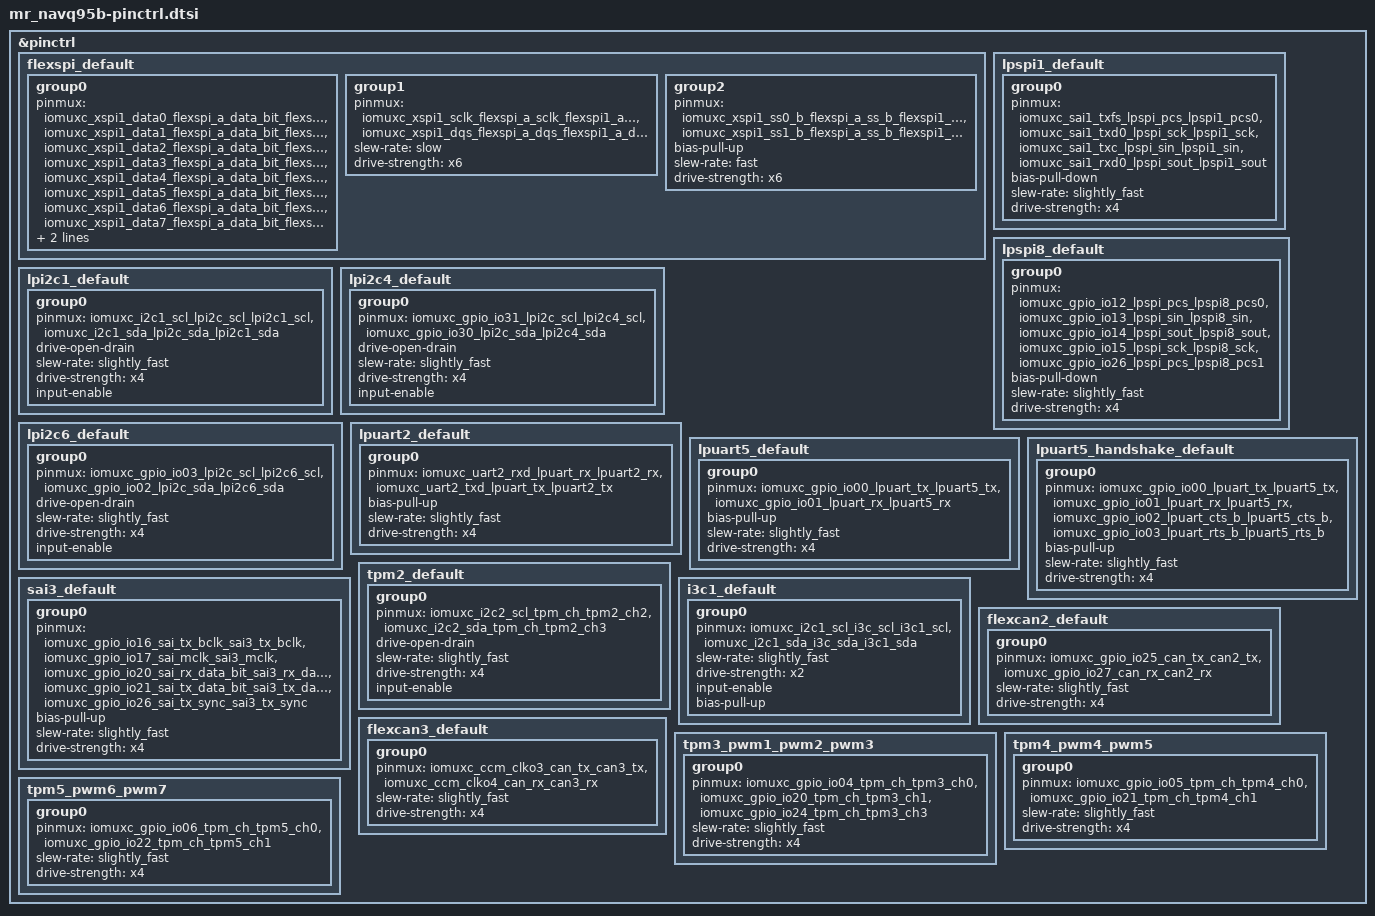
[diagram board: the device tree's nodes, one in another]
/*
 * Copyright 2026 NXP
 *
 * SPDX-License-Identifier: Apache-2.0
 */

#include <nxp/nxp_imx/mimx9596avzxn-pinctrl.dtsi>

&pinctrl {
	flexspi_default: flexspi_default {
		group0 {
			pinmux = <&iomuxc_xspi1_data0_flexspi_a_data_bit_flexspi1_a_data_bit0>,
				 <&iomuxc_xspi1_data1_flexspi_a_data_bit_flexspi1_a_data_bit1>,
				 <&iomuxc_xspi1_data2_flexspi_a_data_bit_flexspi1_a_data_bit2>,
				 <&iomuxc_xspi1_data3_flexspi_a_data_bit_flexspi1_a_data_bit3>,
				 <&iomuxc_xspi1_data4_flexspi_a_data_bit_flexspi1_a_data_bit4>,
				 <&iomuxc_xspi1_data5_flexspi_a_data_bit_flexspi1_a_data_bit5>,
				 <&iomuxc_xspi1_data6_flexspi_a_data_bit_flexspi1_a_data_bit6>,
				 <&iomuxc_xspi1_data7_flexspi_a_data_bit_flexspi1_a_data_bit7>;
			slew-rate = "slow";
			drive-strength = "x1";
		};

		group1 {
			pinmux = <&iomuxc_xspi1_sclk_flexspi_a_sclk_flexspi1_a_sclk>,
				 <&iomuxc_xspi1_dqs_flexspi_a_dqs_flexspi1_a_dqs>;
			slew-rate = "slow";
			drive-strength = "x6";
		};

		group2 {
			pinmux = <&iomuxc_xspi1_ss0_b_flexspi_a_ss_b_flexspi1_a_ss0_b>,
				 <&iomuxc_xspi1_ss1_b_flexspi_a_ss_b_flexspi1_a_ss1_b>;
			bias-pull-up;
			slew-rate = "fast";
			drive-strength = "x6";
		};
	};

	lpspi1_default: lpspi1_default {
		group0 {
			pinmux = <&iomuxc_sai1_txfs_lpspi_pcs_lpspi1_pcs0>,
				 <&iomuxc_sai1_txd0_lpspi_sck_lpspi1_sck>,
				 <&iomuxc_sai1_txc_lpspi_sin_lpspi1_sin>,
				 <&iomuxc_sai1_rxd0_lpspi_sout_lpspi1_sout>;
			bias-pull-down;
			slew-rate = "slightly_fast";
			drive-strength = "x4";
		};
	};

	lpspi8_default: lpspi8_default {
		group0 {
			pinmux = <&iomuxc_gpio_io12_lpspi_pcs_lpspi8_pcs0>,
				 <&iomuxc_gpio_io13_lpspi_sin_lpspi8_sin>,
				 <&iomuxc_gpio_io14_lpspi_sout_lpspi8_sout>,
				 <&iomuxc_gpio_io15_lpspi_sck_lpspi8_sck>,
				 <&iomuxc_gpio_io26_lpspi_pcs_lpspi8_pcs1>;
			bias-pull-down;
			slew-rate = "slightly_fast";
			drive-strength = "x4";
		};
	};

	lpi2c1_default: lpi2c1_default {
		group0 {
			pinmux = <&iomuxc_i2c1_scl_lpi2c_scl_lpi2c1_scl>,
				 <&iomuxc_i2c1_sda_lpi2c_sda_lpi2c1_sda>;
			drive-open-drain;
			slew-rate = "slightly_fast";
			drive-strength = "x4";
			input-enable;
		};
	};

	lpi2c4_default: lpi2c4_default {
		group0 {
			pinmux = <&iomuxc_gpio_io31_lpi2c_scl_lpi2c4_scl>,
				 <&iomuxc_gpio_io30_lpi2c_sda_lpi2c4_sda>;
			drive-open-drain;
			slew-rate = "slightly_fast";
			drive-strength = "x4";
			input-enable;
		};
	};

	lpi2c6_default: lpi2c6_default {
		group0 {
			pinmux = <&iomuxc_gpio_io03_lpi2c_scl_lpi2c6_scl>,
				 <&iomuxc_gpio_io02_lpi2c_sda_lpi2c6_sda>;
			drive-open-drain;
			slew-rate = "slightly_fast";
			drive-strength = "x4";
			input-enable;
		};
	};

	lpuart2_default: lpuart2_default {
		group0 {
			pinmux = <&iomuxc_uart2_rxd_lpuart_rx_lpuart2_rx>,
				 <&iomuxc_uart2_txd_lpuart_tx_lpuart2_tx>;
			bias-pull-up;
			slew-rate = "slightly_fast";
			drive-strength = "x4";
		};
	};

	lpuart5_default: lpuart5_default {
		group0 {
			pinmux = <&iomuxc_gpio_io00_lpuart_tx_lpuart5_tx>,
				 <&iomuxc_gpio_io01_lpuart_rx_lpuart5_rx>;
			bias-pull-up;
			slew-rate = "slightly_fast";
			drive-strength = "x4";
		};
	};

	lpuart5_handshake_default: lpuart5_handshake_default {
		group0 {
			pinmux = <&iomuxc_gpio_io00_lpuart_tx_lpuart5_tx>,
				 <&iomuxc_gpio_io01_lpuart_rx_lpuart5_rx>,
				 <&iomuxc_gpio_io02_lpuart_cts_b_lpuart5_cts_b>,
				 <&iomuxc_gpio_io03_lpuart_rts_b_lpuart5_rts_b>;
			bias-pull-up;
			slew-rate = "slightly_fast";
			drive-strength = "x4";
		};
	};

	sai3_default: sai3_default {
		group0 {
			pinmux = <&iomuxc_gpio_io16_sai_tx_bclk_sai3_tx_bclk>,
				 <&iomuxc_gpio_io17_sai_mclk_sai3_mclk>,
				 <&iomuxc_gpio_io20_sai_rx_data_bit_sai3_rx_data_bit0>,
				 <&iomuxc_gpio_io21_sai_tx_data_bit_sai3_tx_data_bit0>,
				 <&iomuxc_gpio_io26_sai_tx_sync_sai3_tx_sync>;
			bias-pull-up;
			slew-rate = "slightly_fast";
			drive-strength = "x4";
		};
	};

	tpm2_default: tpm2_default {
		group0 {
			pinmux = <&iomuxc_i2c2_scl_tpm_ch_tpm2_ch2>,
				 <&iomuxc_i2c2_sda_tpm_ch_tpm2_ch3>;
			drive-open-drain;
			slew-rate = "slightly_fast";
			drive-strength = "x4";
			input-enable;
		};
	};

	i3c1_default: i3c1_default {
		group0 {
			pinmux = <&iomuxc_i2c1_scl_i3c_scl_i3c1_scl>,
				 <&iomuxc_i2c1_sda_i3c_sda_i3c1_sda>;
			slew-rate = "slightly_fast";
			drive-strength = "x2";
			input-enable;
			bias-pull-up;
		};
	};

	flexcan2_default: flexcan2_default {
		group0 {
			pinmux = <&iomuxc_gpio_io25_can_tx_can2_tx>,
				 <&iomuxc_gpio_io27_can_rx_can2_rx>;
			slew-rate = "slightly_fast";
			drive-strength = "x4";
		};
	};

	flexcan3_default: flexcan3_default {
		group0 {
			pinmux = <&iomuxc_ccm_clko3_can_tx_can3_tx>,
				 <&iomuxc_ccm_clko4_can_rx_can3_rx>;
			slew-rate = "slightly_fast";
			drive-strength = "x4";
		};
	};

	/* pwm pins */
	tpm3_pwm1_pwm2_pwm3: tpm3_pwm1_pwm2_pwm3 {
		group0 {
			pinmux = <&iomuxc_gpio_io04_tpm_ch_tpm3_ch0>,
				 <&iomuxc_gpio_io20_tpm_ch_tpm3_ch1>,
				 <&iomuxc_gpio_io24_tpm_ch_tpm3_ch3>;
			slew-rate = "slightly_fast";
			drive-strength = "x4";
		};
	};

	tpm4_pwm4_pwm5: tpm4_pwm4_pwm5 {
		group0 {
			pinmux = <&iomuxc_gpio_io05_tpm_ch_tpm4_ch0>,
				 <&iomuxc_gpio_io21_tpm_ch_tpm4_ch1>;
			slew-rate = "slightly_fast";
			drive-strength = "x4";
		};
	};

	tpm5_pwm6_pwm7: tpm5_pwm6_pwm7 {
		group0 {
			pinmux = <&iomuxc_gpio_io06_tpm_ch_tpm5_ch0>,
				 <&iomuxc_gpio_io22_tpm_ch_tpm5_ch1>;
			slew-rate = "slightly_fast";
			drive-strength = "x4";
		};
	};
};
